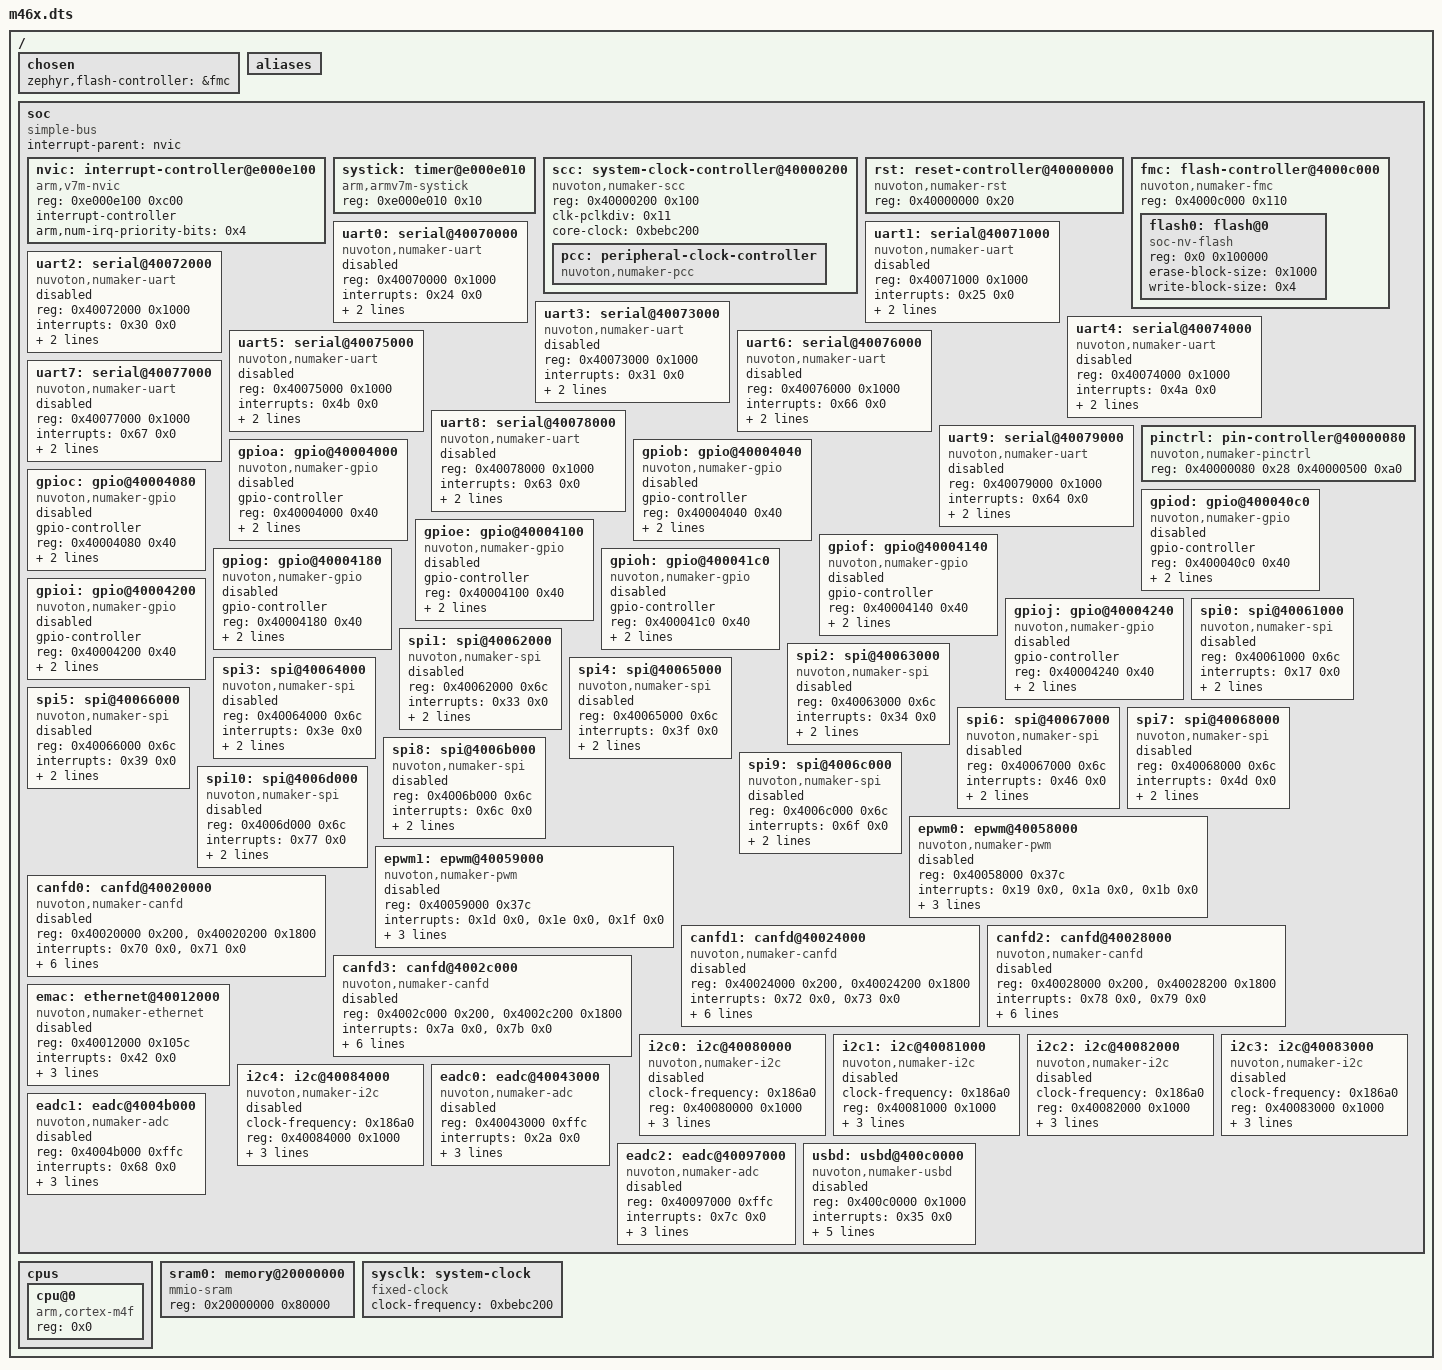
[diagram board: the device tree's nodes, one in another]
/dts-v1/;

/ {
	#address-cells = < 0x1 >;
	#size-cells = < 0x1 >;
	chosen {
		zephyr,flash-controller = &fmc;
	};
	aliases {
	};
	soc {
		#address-cells = < 0x1 >;
		#size-cells = < 0x1 >;
		compatible = "simple-bus";
		interrupt-parent = < &nvic >;
		ranges;
		nvic: interrupt-controller@e000e100 {
			#address-cells = < 0x1 >;
			compatible = "arm,v7m-nvic";
			reg = < 0xe000e100 0xc00 >;
			interrupt-controller;
			#interrupt-cells = < 0x2 >;
			arm,num-irq-priority-bits = < 0x4 >;
			phandle = < 0x1 >;
		};
		systick: timer@e000e010 {
			compatible = "arm,armv7m-systick";
			reg = < 0xe000e010 0x10 >;
		};
		scc: system-clock-controller@40000200 {
			compatible = "nuvoton,numaker-scc";
			reg = < 0x40000200 0x100 >;
			#clock-cells = < 0x0 >;
			clk-pclkdiv = < 0x11 >;
			core-clock = < 0xbebc200 >;
			pcc: peripheral-clock-controller {
				compatible = "nuvoton,numaker-pcc";
				#clock-cells = < 0x3 >;
				phandle = < 0x3 >;
			};
		};
		rst: reset-controller@40000000 {
			compatible = "nuvoton,numaker-rst";
			reg = < 0x40000000 0x20 >;
			#reset-cells = < 0x1 >;
			status = "okay";
			phandle = < 0x2 >;
		};
		fmc: flash-controller@4000c000 {
			compatible = "nuvoton,numaker-fmc";
			reg = < 0x4000c000 0x110 >;
			#address-cells = < 0x1 >;
			#size-cells = < 0x1 >;
			flash0: flash@0 {
				compatible = "soc-nv-flash";
				reg = < 0x0 0x100000 >;
				erase-block-size = < 0x1000 >;
				write-block-size = < 0x4 >;
			};
		};
		uart0: serial@40070000 {
			compatible = "nuvoton,numaker-uart";
			reg = < 0x40070000 0x1000 >;
			interrupts = < 0x24 0x0 >;
			resets = < &rst 0x4000010 >;
			clocks = < &pcc 0x24f03d10 0x3000000 0x0 >;
			status = "disabled";
		};
		uart1: serial@40071000 {
			compatible = "nuvoton,numaker-uart";
			reg = < 0x40071000 0x1000 >;
			interrupts = < 0x25 0x0 >;
			resets = < &rst 0x4000011 >;
			clocks = < &pcc 0x24f43d91 0xc000000 0x0 >;
			status = "disabled";
		};
		uart2: serial@40072000 {
			compatible = "nuvoton,numaker-uart";
			reg = < 0x40072000 0x1000 >;
			interrupts = < 0x30 0x0 >;
			resets = < &rst 0x4000012 >;
			clocks = < &pcc 0x2cf13c12 0x3000000 0x0 >;
			status = "disabled";
		};
		uart3: serial@40073000 {
			compatible = "nuvoton,numaker-uart";
			reg = < 0x40073000 0x1000 >;
			interrupts = < 0x31 0x0 >;
			resets = < &rst 0x4000013 >;
			clocks = < &pcc 0x2cf53c93 0xc000000 0x0 >;
			status = "disabled";
		};
		uart4: serial@40074000 {
			compatible = "nuvoton,numaker-uart";
			reg = < 0x40074000 0x1000 >;
			interrupts = < 0x4a 0x0 >;
			resets = < &rst 0x4000014 >;
			clocks = < &pcc 0x2cf93d14 0x30000000 0x0 >;
			status = "disabled";
		};
		uart5: serial@40075000 {
			compatible = "nuvoton,numaker-uart";
			reg = < 0x40075000 0x1000 >;
			interrupts = < 0x4b 0x0 >;
			resets = < &rst 0x4000015 >;
			clocks = < &pcc 0x2cfd3d95 0xc0000000 0x0 >;
			status = "disabled";
		};
		uart6: serial@40076000 {
			compatible = "nuvoton,numaker-uart";
			reg = < 0x40076000 0x1000 >;
			interrupts = < 0x66 0x0 >;
			resets = < &rst 0x4000016 >;
			clocks = < &pcc 0x2ce93e16 0x300000 0x0 >;
			status = "disabled";
		};
		uart7: serial@40077000 {
			compatible = "nuvoton,numaker-uart";
			reg = < 0x40077000 0x1000 >;
			interrupts = < 0x67 0x0 >;
			resets = < &rst 0x4000017 >;
			clocks = < &pcc 0x2ced3e97 0xc00000 0x0 >;
			status = "disabled";
		};
		uart8: serial@40078000 {
			compatible = "nuvoton,numaker-uart";
			reg = < 0x40078000 0x1000 >;
			interrupts = < 0x63 0x0 >;
			resets = < &rst 0x18000010 >;
			clocks = < &pcc 0x68e97e10 0x300000 0x0 >;
			status = "disabled";
		};
		uart9: serial@40079000 {
			compatible = "nuvoton,numaker-uart";
			reg = < 0x40079000 0x1000 >;
			interrupts = < 0x64 0x0 >;
			resets = < &rst 0x18000011 >;
			clocks = < &pcc 0x68ed7e91 0xc00000 0x0 >;
			status = "disabled";
		};
		pinctrl: pin-controller@40000080 {
			compatible = "nuvoton,numaker-pinctrl";
			reg = < 0x40000080 0x28 0x40000500 0xa0 >;
			reg-names = "mfos", "mfp";
			status = "okay";
		};
		gpioa: gpio@40004000 {
			compatible = "nuvoton,numaker-gpio";
			gpio-controller;
			#gpio-cells = < 0x2 >;
			reg = < 0x40004000 0x40 >;
			clocks = < &pcc 0x18 0x0 0x0 >;
			status = "disabled";
			interrupts = < 0x10 0x2 >;
		};
		gpiob: gpio@40004040 {
			compatible = "nuvoton,numaker-gpio";
			gpio-controller;
			#gpio-cells = < 0x2 >;
			reg = < 0x40004040 0x40 >;
			clocks = < &pcc 0x19 0x0 0x0 >;
			status = "disabled";
			interrupts = < 0x11 0x2 >;
		};
		gpioc: gpio@40004080 {
			compatible = "nuvoton,numaker-gpio";
			gpio-controller;
			#gpio-cells = < 0x2 >;
			reg = < 0x40004080 0x40 >;
			clocks = < &pcc 0x1a 0x0 0x0 >;
			status = "disabled";
			interrupts = < 0x12 0x2 >;
		};
		gpiod: gpio@400040c0 {
			compatible = "nuvoton,numaker-gpio";
			gpio-controller;
			#gpio-cells = < 0x2 >;
			reg = < 0x400040c0 0x40 >;
			clocks = < &pcc 0x1b 0x0 0x0 >;
			status = "disabled";
			interrupts = < 0x13 0x2 >;
		};
		gpioe: gpio@40004100 {
			compatible = "nuvoton,numaker-gpio";
			gpio-controller;
			#gpio-cells = < 0x2 >;
			reg = < 0x40004100 0x40 >;
			clocks = < &pcc 0x1c 0x0 0x0 >;
			status = "disabled";
			interrupts = < 0x14 0x2 >;
		};
		gpiof: gpio@40004140 {
			compatible = "nuvoton,numaker-gpio";
			gpio-controller;
			#gpio-cells = < 0x2 >;
			reg = < 0x40004140 0x40 >;
			clocks = < &pcc 0x1d 0x0 0x0 >;
			status = "disabled";
			interrupts = < 0x15 0x2 >;
		};
		gpiog: gpio@40004180 {
			compatible = "nuvoton,numaker-gpio";
			gpio-controller;
			#gpio-cells = < 0x2 >;
			reg = < 0x40004180 0x40 >;
			clocks = < &pcc 0x1e 0x0 0x0 >;
			status = "disabled";
			interrupts = < 0x48 0x2 >;
		};
		gpioh: gpio@400041c0 {
			compatible = "nuvoton,numaker-gpio";
			gpio-controller;
			#gpio-cells = < 0x2 >;
			reg = < 0x400041c0 0x40 >;
			clocks = < &pcc 0x1f 0x0 0x0 >;
			status = "disabled";
			interrupts = < 0x58 0x2 >;
		};
		gpioi: gpio@40004200 {
			compatible = "nuvoton,numaker-gpio";
			gpio-controller;
			#gpio-cells = < 0x2 >;
			reg = < 0x40004200 0x40 >;
			clocks = < &pcc 0x80000018 0x0 0x0 >;
			status = "disabled";
			interrupts = < 0x6e 0x2 >;
		};
		gpioj: gpio@40004240 {
			compatible = "nuvoton,numaker-gpio";
			gpio-controller;
			#gpio-cells = < 0x2 >;
			reg = < 0x40004240 0x40 >;
			clocks = < &pcc 0x80000019 0x0 0x0 >;
			status = "disabled";
			interrupts = < 0x3d 0x2 >;
		};
		spi0: spi@40061000 {
			compatible = "nuvoton,numaker-spi";
			reg = < 0x40061000 0x6c >;
			interrupts = < 0x17 0x0 >;
			resets = < &rst 0x400000d >;
			clocks = < &pcc 0x29c8000d 0x30 0x0 >;
			#address-cells = < 0x1 >;
			#size-cells = < 0x0 >;
			status = "disabled";
		};
		spi1: spi@40062000 {
			compatible = "nuvoton,numaker-spi";
			reg = < 0x40062000 0x6c >;
			interrupts = < 0x33 0x0 >;
			resets = < &rst 0x400000e >;
			clocks = < &pcc 0x29d8000e 0x3000 0x0 >;
			#address-cells = < 0x1 >;
			#size-cells = < 0x0 >;
			status = "disabled";
		};
		spi2: spi@40063000 {
			compatible = "nuvoton,numaker-spi";
			reg = < 0x40063000 0x6c >;
			interrupts = < 0x34 0x0 >;
			resets = < &rst 0x400000f >;
			clocks = < &pcc 0x2dd2000f 0x600 0x0 >;
			#address-cells = < 0x1 >;
			#size-cells = < 0x0 >;
			status = "disabled";
		};
		spi3: spi@40064000 {
			compatible = "nuvoton,numaker-spi";
			reg = < 0x40064000 0x6c >;
			interrupts = < 0x3e 0x0 >;
			resets = < &rst 0x8000006 >;
			clocks = < &pcc 0x4dd80006 0x3000 0x0 >;
			#address-cells = < 0x1 >;
			#size-cells = < 0x0 >;
			status = "disabled";
		};
		spi4: spi@40065000 {
			compatible = "nuvoton,numaker-spi";
			reg = < 0x40065000 0x6c >;
			interrupts = < 0x3f 0x0 >;
			resets = < &rst 0x8000007 >;
			clocks = < &pcc 0x51c00007 0x3 0x0 >;
			#address-cells = < 0x1 >;
			#size-cells = < 0x0 >;
			status = "disabled";
		};
		spi5: spi@40066000 {
			compatible = "nuvoton,numaker-spi";
			reg = < 0x40066000 0x6c >;
			interrupts = < 0x39 0x0 >;
			resets = < &rst 0x18000008 >;
			clocks = < &pcc 0x71c80008 0x30 0x0 >;
			#address-cells = < 0x1 >;
			#size-cells = < 0x0 >;
			status = "disabled";
		};
		spi6: spi@40067000 {
			compatible = "nuvoton,numaker-spi";
			reg = < 0x40067000 0x6c >;
			interrupts = < 0x46 0x0 >;
			resets = < &rst 0x18000009 >;
			clocks = < &pcc 0x71d00009 0x300 0x0 >;
			#address-cells = < 0x1 >;
			#size-cells = < 0x0 >;
			status = "disabled";
		};
		spi7: spi@40068000 {
			compatible = "nuvoton,numaker-spi";
			reg = < 0x40068000 0x6c >;
			interrupts = < 0x4d 0x0 >;
			resets = < &rst 0x1800000a >;
			clocks = < &pcc 0x71d8000a 0x3000 0x0 >;
			#address-cells = < 0x1 >;
			#size-cells = < 0x0 >;
			status = "disabled";
		};
		spi8: spi@4006b000 {
			compatible = "nuvoton,numaker-spi";
			reg = < 0x4006b000 0x6c >;
			interrupts = < 0x6c 0x0 >;
			resets = < &rst 0x1800000b >;
			clocks = < &pcc 0x71e0000b 0x30000 0x0 >;
			#address-cells = < 0x1 >;
			#size-cells = < 0x0 >;
			status = "disabled";
		};
		spi9: spi@4006c000 {
			compatible = "nuvoton,numaker-spi";
			reg = < 0x4006c000 0x6c >;
			interrupts = < 0x6f 0x0 >;
			resets = < &rst 0x1800000c >;
			clocks = < &pcc 0x71e8000c 0x300000 0x0 >;
			#address-cells = < 0x1 >;
			#size-cells = < 0x0 >;
			status = "disabled";
		};
		spi10: spi@4006d000 {
			compatible = "nuvoton,numaker-spi";
			reg = < 0x4006d000 0x6c >;
			interrupts = < 0x77 0x0 >;
			resets = < &rst 0x1800000d >;
			clocks = < &pcc 0x71f0000d 0x3000000 0x0 >;
			#address-cells = < 0x1 >;
			#size-cells = < 0x0 >;
			status = "disabled";
		};
		epwm0: epwm@40058000 {
			compatible = "nuvoton,numaker-pwm";
			reg = < 0x40058000 0x37c >;
			interrupts = < 0x19 0x0 >, < 0x1a 0x0 >, < 0x1b 0x0 >;
			interrupt-names = "pair0", "pair1", "pair2";
			resets = < &rst 0x8000010 >;
			prescaler = < 0x13 >;
			clocks = < &pcc 0x48400010 0x1 0x0 >;
			#pwm-cells = < 0x3 >;
			status = "disabled";
		};
		epwm1: epwm@40059000 {
			compatible = "nuvoton,numaker-pwm";
			reg = < 0x40059000 0x37c >;
			interrupts = < 0x1d 0x0 >, < 0x1e 0x0 >, < 0x1f 0x0 >;
			interrupt-names = "pair0", "pair1", "pair2";
			resets = < &rst 0x8000011 >;
			prescaler = < 0x13 >;
			clocks = < &pcc 0x48420011 0x2 0x0 >;
			#pwm-cells = < 0x3 >;
			status = "disabled";
		};
		canfd0: canfd@40020000 {
			compatible = "nuvoton,numaker-canfd";
			reg = < 0x40020000 0x200 >, < 0x40020200 0x1800 >;
			reg-names = "m_can", "message_ram";
			interrupts = < 0x70 0x0 >, < 0x71 0x0 >;
			interrupt-names = "int0", "int1";
			resets = < &rst 0x14 >;
			clocks = < &pcc 0x80f17c14 0x2000000 0x0 >;
			bosch,mram-cfg = < 0x0 0xc 0xa 0x3 0x3 0x3 0x3 0x3 >;
			status = "disabled";
			sample-point = < 0x36b >;
			sample-point-data = < 0x36b >;
		};
		canfd1: canfd@40024000 {
			compatible = "nuvoton,numaker-canfd";
			reg = < 0x40024000 0x200 >, < 0x40024200 0x1800 >;
			reg-names = "m_can", "message_ram";
			interrupts = < 0x72 0x0 >, < 0x73 0x0 >;
			interrupt-names = "int0", "int1";
			resets = < &rst 0x15 >;
			clocks = < &pcc 0x80f57c95 0x8000000 0x0 >;
			bosch,mram-cfg = < 0x0 0xc 0xa 0x3 0x3 0x3 0x3 0x3 >;
			status = "disabled";
			sample-point = < 0x36b >;
			sample-point-data = < 0x36b >;
		};
		canfd2: canfd@40028000 {
			compatible = "nuvoton,numaker-canfd";
			reg = < 0x40028000 0x200 >, < 0x40028200 0x1800 >;
			reg-names = "m_can", "message_ram";
			interrupts = < 0x78 0x0 >, < 0x79 0x0 >;
			interrupt-names = "int0", "int1";
			resets = < &rst 0x16 >;
			clocks = < &pcc 0x80f97d16 0x20000000 0x0 >;
			bosch,mram-cfg = < 0x0 0xc 0xa 0x3 0x3 0x3 0x3 0x3 >;
			status = "disabled";
			sample-point = < 0x36b >;
			sample-point-data = < 0x36b >;
		};
		canfd3: canfd@4002c000 {
			compatible = "nuvoton,numaker-canfd";
			reg = < 0x4002c000 0x200 >, < 0x4002c200 0x1800 >;
			reg-names = "m_can", "message_ram";
			interrupts = < 0x7a 0x0 >, < 0x7b 0x0 >;
			interrupt-names = "int0", "int1";
			resets = < &rst 0x17 >;
			clocks = < &pcc 0x80fd7d97 0x80000000 0x0 >;
			bosch,mram-cfg = < 0x0 0xc 0xa 0x3 0x3 0x3 0x3 0x3 >;
			status = "disabled";
			sample-point = < 0x36b >;
			sample-point-data = < 0x36b >;
		};
		emac: ethernet@40012000 {
			compatible = "nuvoton,numaker-ethernet";
			reg = < 0x40012000 0x105c >;
			interrupts = < 0x42 0x0 >;
			resets = < &rst 0x5 >;
			phy-addr = < 0x1 >;
			clocks = < &pcc 0xfe05 0x0 0x0 >;
			status = "disabled";
		};
		i2c0: i2c@40080000 {
			compatible = "nuvoton,numaker-i2c";
			clock-frequency = < 0x186a0 >;
			reg = < 0x40080000 0x1000 >;
			interrupts = < 0x26 0x0 >;
			resets = < &rst 0x4000008 >;
			clocks = < &pcc 0x20000008 0x0 0x0 >;
			status = "disabled";
			#address-cells = < 0x1 >;
			#size-cells = < 0x0 >;
		};
		i2c1: i2c@40081000 {
			compatible = "nuvoton,numaker-i2c";
			clock-frequency = < 0x186a0 >;
			reg = < 0x40081000 0x1000 >;
			interrupts = < 0x27 0x0 >;
			resets = < &rst 0x4000009 >;
			clocks = < &pcc 0x20000009 0x0 0x0 >;
			status = "disabled";
			#address-cells = < 0x1 >;
			#size-cells = < 0x0 >;
		};
		i2c2: i2c@40082000 {
			compatible = "nuvoton,numaker-i2c";
			clock-frequency = < 0x186a0 >;
			reg = < 0x40082000 0x1000 >;
			interrupts = < 0x52 0x0 >;
			resets = < &rst 0x400000a >;
			clocks = < &pcc 0x2000000a 0x0 0x0 >;
			status = "disabled";
			#address-cells = < 0x1 >;
			#size-cells = < 0x0 >;
		};
		i2c3: i2c@40083000 {
			compatible = "nuvoton,numaker-i2c";
			clock-frequency = < 0x186a0 >;
			reg = < 0x40083000 0x1000 >;
			interrupts = < 0x53 0x0 >;
			resets = < &rst 0x400000b >;
			clocks = < &pcc 0x2000000b 0x0 0x0 >;
			status = "disabled";
			#address-cells = < 0x1 >;
			#size-cells = < 0x0 >;
		};
		i2c4: i2c@40084000 {
			compatible = "nuvoton,numaker-i2c";
			clock-frequency = < 0x186a0 >;
			reg = < 0x40084000 0x1000 >;
			interrupts = < 0x76 0x0 >;
			resets = < &rst 0x8000003 >;
			clocks = < &pcc 0x40000003 0x0 0x0 >;
			status = "disabled";
			#address-cells = < 0x1 >;
			#size-cells = < 0x0 >;
		};
		eadc0: eadc@40043000 {
			compatible = "nuvoton,numaker-adc";
			reg = < 0x40043000 0xffc >;
			interrupts = < 0x2a 0x0 >;
			resets = < &rst 0x400001c >;
			clocks = < &pcc 0x20d43e1c 0x800 0xb0000 >;
			channels = < 0x13 >;
			status = "disabled";
			#io-channel-cells = < 0x1 >;
		};
		eadc1: eadc@4004b000 {
			compatible = "nuvoton,numaker-adc";
			reg = < 0x4004b000 0xffc >;
			interrupts = < 0x68 0x0 >;
			resets = < &rst 0x800001f >;
			clocks = < &pcc 0x40d8001f 0x2000 0xb000000 >;
			channels = < 0x13 >;
			status = "disabled";
			#io-channel-cells = < 0x1 >;
		};
		eadc2: eadc@40097000 {
			compatible = "nuvoton,numaker-adc";
			reg = < 0x40097000 0xffc >;
			interrupts = < 0x7c 0x0 >;
			resets = < &rst 0x18000006 >;
			clocks = < &pcc 0x60dcbf06 0x8000 0xb000000 >;
			channels = < 0x13 >;
			status = "disabled";
			#io-channel-cells = < 0x1 >;
		};
		usbd: usbd@400c0000 {
			compatible = "nuvoton,numaker-usbd";
			reg = < 0x400c0000 0x1000 >;
			interrupts = < 0x35 0x0 >;
			resets = < &rst 0x400001b >;
			clocks = < &pcc 0x20503c9b 0x100 0x10 >;
			dma-buffer-size = < 0x600 >;
			status = "disabled";
			num-bidir-endpoints = < 0x19 >;
			disallow-iso-in-out-same-number;
		};
	};
	cpus {
		#address-cells = < 0x1 >;
		#size-cells = < 0x0 >;
		cpu@0 {
			device_type = "cpu";
			compatible = "arm,cortex-m4f";
			reg = < 0x0 >;
		};
	};
	sram0: memory@20000000 {
		compatible = "mmio-sram";
		reg = < 0x20000000 0x80000 >;
	};
	sysclk: system-clock {
		compatible = "fixed-clock";
		clock-frequency = < 0xbebc200 >;
		#clock-cells = < 0x0 >;
	};
};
